# MCU_NAVSS0_SEC_PROXY0_CFG_SCFG register map
Vendor: Texas Instruments
Peripheral module from a debugger description file (folder am65x).
Registers are 32-bit, read-write, reset 0x0 unless marked. A register's access mark holds for its fields unless they carry their own. Offsets are as the file gives them; lines under a group give offsets from that group; [hi:lo] are bit positions; {n}, {i} and the like mark numbered series; 'fields as' and 'values as' point back to an identical list; <NAME> marks a mode.

## MCU_NAVSS0_SEC_PROXY0_CFG_SCFG
0x00 SEC_PROXY_BUFFER_L — The Buffer Register defines the pointer for the external buffer.
  [31:0] BASE_L — The base address for the external buffer, lower 32 bits.
0x04 SEC_PROXY_BUFFER_H — The Buffer Register defines the pointer for the external buffer.
  [15:0] BASE_H — The base address for the external buffer, upper 16 bits.
0x08 SEC_PROXY_TARGET_L reset 0x38300000 — The Target Register defines the pointer for the external target.
  [31:0] BASE_L — The base address for the external target, lower 32 bits.
0x0C SEC_PROXY_TARGET_H — The Target Register defines the pointer for the external target.
  [15:0] BASE_H — The base address for the external target, upper 16 bits.
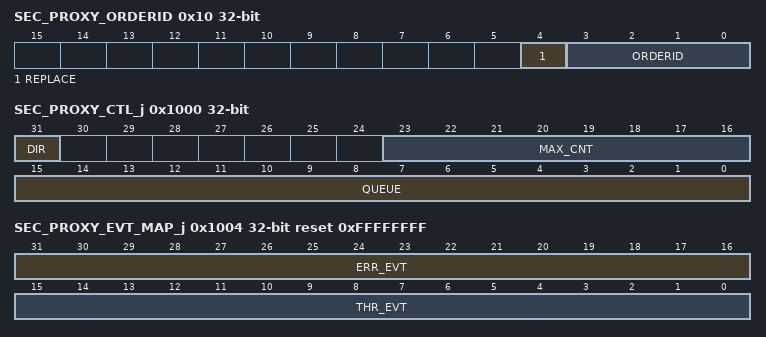
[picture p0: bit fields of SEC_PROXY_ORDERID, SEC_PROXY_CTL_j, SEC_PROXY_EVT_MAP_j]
0x10 SEC_PROXY_ORDERID — The Buffer OrderID Register contains the bus value for the buffer memory access.
  [4] REPLACE — Indicates to replace the bus OrderID value for the buffer access with the ORDERID register field. 0 = bypass and use the OrderID from the source transaction for the destination transaction. 1 = use the ORDERID register field value for the destination transaction.
  [3:0] ORDERID — Defines the bus OrderID value for the buffer access.
0x1000 SEC_PROXY_CTL_j — The Control Register defines controls for proxy thread a. Offset = 1000h + (j * 1000h); where j = 0h to 9Fh for NAVSS0_SEC_PROXY0_CFG_SCFG j = 0h to 59h for MCU_NAVSS0_SEC_PROXY0_CFG_SCFG
  [31] DIR — Direction for the proxy thread. 0 = outbound, write only. 1 = inbound, read only.
  [23:16] MAX_CNT — Max message count allowed for an outbound proxy thread. Is not used otherwise.
  [15:0] QUEUE — Queue number in the target to use for the proxy thread. If the target base does not start at queue 0 then this is the relative queue number from that base queue.
0x1004 SEC_PROXY_EVT_MAP_j reset 0xFFFFFFFF — The Event Map Register defines the event numbers for proxy thread a. Offset = 1004h + (j * 1000h); where j = 0h to 9Fh for NAVSS0_SEC_PROXY0_CFG_SCFG j = 0h to 59h for MCU_NAVSS0_SEC_PROXY0_CFG_SCFG
  [31:16] ERR_EVT — Event number for an error from the proxy thread.
  [15:0] THR_EVT — Event number for a threshold event from the proxy thread.
0x1008 SEC_PROXY_DST_j — The Destination Register defines the destination proxy thread for outbound proxy thread a. Offset = 1008h + (j * 1000h); where j = 0h to 9Fh for NAVSS0_SEC_PROXY0_CFG_SCFG j = 0h to 59h for MCU_NAVSS0_SEC_PROXY0_CFG_SCFG
  [15:0] THREAD — The proxy thread that is the destination of messages from this outbound proxy thread, based on the queue numbers. This is ignored for inbound proxy threads.
